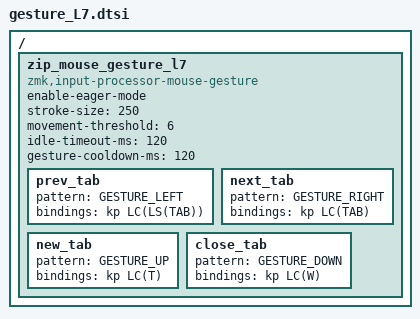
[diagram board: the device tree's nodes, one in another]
/ {
  zip_mouse_gesture_l7: zip_mouse_gesture_l7 {
    compatible = "zmk,input-processor-mouse-gesture";

    enable-eager-mode;
    stroke-size = <250>;
    movement-threshold = <6>;
    idle-timeout-ms = <120>;
    gesture-cooldown-ms = <120>;

    prev_tab { pattern = <GESTURE_LEFT>;  bindings = <&kp LC(LS(TAB))>; };
    next_tab { pattern = <GESTURE_RIGHT>; bindings = <&kp LC(TAB)>; };
    new_tab  { pattern = <GESTURE_UP>;    bindings = <&kp LC(T)>; };
    close_tab{ pattern = <GESTURE_DOWN>;  bindings = <&kp LC(W)>; };
  };
};
